# ATSAMC21E17A register map
Vendor: Microchip Technology; Series: SAMC21; File version: 0
CPU: CM0+ r0p0, selectable endian, MPU, no FPU, 2 interrupt priority bits
Registers are 32-bit, read-write, reset 0x0 unless marked. A register's access mark holds for its fields unless they carry their own. Offsets are from the block's base; [hi:lo] are bit positions; lines under a group give offsets from that group; {n}, {i} and the like mark numbered series; 'fields as' and 'values as' point back to an identical list.

## PORT — Port Module
Base 0x41000000; register names take the prefix PORT_
Same registers: PORT_IOBUS 0x60000000 (register names take the prefix PORT_IOBUS_)
{0x0+0x80*i} GROUP[{i}] (i=0..0) group
  0x00 DIR — Data Direction
  0x04 DIRCLR — Data Direction Clear
    [31:0] DIRCLR write-1-clears — Port Data Direction Clear
  0x08 DIRSET — Data Direction Set
    [31:0] DIRSET write-1-sets — Port Data Direction Set
  0x0C DIRTGL — Data Direction Toggle
    [31:0] DIRTGL write-1-toggles — Port Data Direction Toggle
  0x10 OUT — Data Output Value
  0x14 OUTCLR — Data Output Value Clear
    [31:0] OUTCLR write-1-clears — PORT Data Output Value Clear
  0x18 OUTSET — Data Output Value Set
    [31:0] OUTSET write-1-sets — PORT Data Output Value Set
  0x1C OUTTGL — Data Output Value Toggle
    [31:0] OUTTGL write-1-toggles — PORT Data Output Value Toggle
  0x20 IN ro — Data Input Value
  0x24 CTRL — Control
    [31:0] SAMPLING — Input Sampling Mode
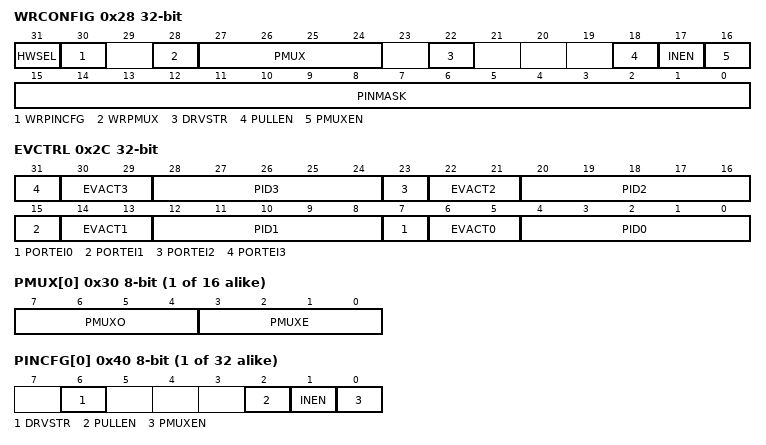
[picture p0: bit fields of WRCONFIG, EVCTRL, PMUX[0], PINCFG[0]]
  0x28 WRCONFIG wo — Write Configuration
    [31] HWSEL — Half-Word Select
    [30] WRPINCFG — Write PINCFG Registers
    [28] WRPMUX — Write PMUX Registers
    [27:24] PMUX — Peripheral Multiplexing Template
    [22] DRVSTR — Output Driver Strength Selection
    [18] PULLEN — Pull Enable
    [17] INEN — Input Enable
    [16] PMUXEN — Select Peripheral Multiplexer
    [15:0] PINMASK — Pin Mask for Multiple Pin Configuration
  0x2C EVCTRL — Event Input Control
    [8n+7] PORTEI{n} (n=0..3) — Port Event Enable Input {n}
    [30:29] EVACT3 — Port Event Action 3
    [8n+4:8n] PID{n} (n=0..3) — Port Event Pin Identifier {n}
    [22:21] EVACT2 — Port Event Action 2
    [14:13] EVACT1 — Port Event Action 1
    [6:5] EVACT0 — Port Event Action 0
      0=OUT (Event output to pin); 1=SET (Set output register of pin on event); 2=CLR (Clear output register of pin on event); 3=TGL (Toggle output register of pin on event)
  {0x30+j} PMUX[{j}] (j=0..15) 8-bit — Peripheral Multiplexing n
    [7:4] PMUXO — Peripheral Multiplexing for Odd-Numbered Pin
    [3:0] PMUXE — Peripheral Multiplexing for Even-Numbered Pin
  {0x40+j} PINCFG[{j}] (j=0..31) 8-bit — Pin Configuration n
    [6] DRVSTR — Output Driver Strength Selection
    [2] PULLEN — Pull Enable
    [1] INEN — Input Enable
    [0] PMUXEN — Select Peripheral Multiplexer

## PTC — Peripheral Touch Controller
Base 0x42005800; register names take the prefix PTC_

## RSTC — Reset Controller
Base 0x40000C00; register names take the prefix RSTC_
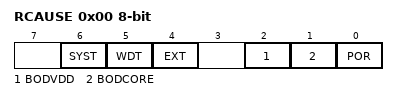
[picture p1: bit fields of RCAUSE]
0x00 RCAUSE 8-bit ro — Reset Cause
  [6] SYST — System Reset Request
  [5] WDT — Watchdog Reset
  [4] EXT — External Reset
  [2] BODVDD — Brown Out VDD Detector Reset
  [1] BODCORE — Brown Out CORE Detector Reset
  [0] POR — Power On Reset

## SUPC — Supply Controller
Base 0x40001800; register names take the prefix SUPC_
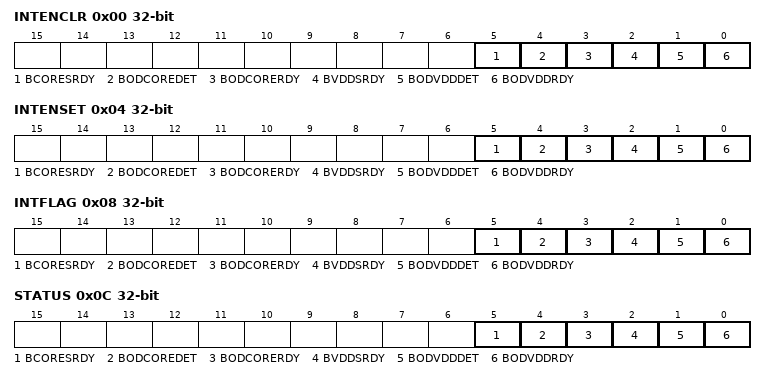
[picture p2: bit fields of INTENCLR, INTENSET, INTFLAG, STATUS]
0x00 INTENCLR — Interrupt Enable Clear
  [5] BCORESRDY — BODCORE Synchronization Ready
  [4] BODCOREDET — BODCORE Detection
  [3] BODCORERDY — BODCORE Ready
  [2] BVDDSRDY — BODVDD Synchronization Ready
  [1] BODVDDDET — BODVDD Detection
  [0] BODVDDRDY — BODVDD Ready
0x04 INTENSET — Interrupt Enable Set
  fields as INTENCLR
0x08 INTFLAG — Interrupt Flag Status and Clear
  [5] BCORESRDY — BODCORE Synchronization Ready
  [4] BODCOREDET — BODCORE Detection
  [3] BODCORERDY — BODCORE Ready
  [2] BVDDSRDY write-1-clears — BODVDD Synchronization Ready
  [1] BODVDDDET write-1-clears — BODVDD Detection
  [0] BODVDDRDY write-1-clears — BODVDD Ready
0x0C STATUS ro — Power and Clocks Status
  fields as INTENCLR
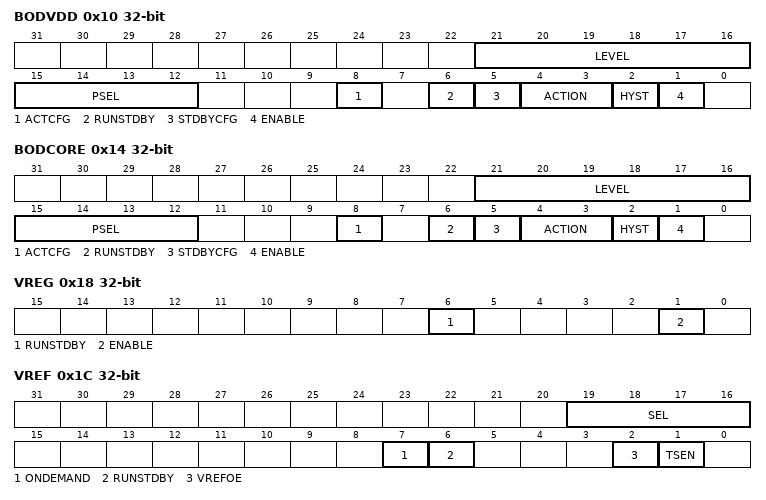
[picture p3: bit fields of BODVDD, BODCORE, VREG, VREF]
0x10 BODVDD — BODVDD Control
  [21:16] LEVEL — Threshold Level for VDD
  [15:12] PSEL — Prescaler Select
    0=DIV2 (Divide clock by 2); 1=DIV4 (Divide clock by 4); 2=DIV8 (Divide clock by 8); 3=DIV16 (Divide clock by 16); 4=DIV32 (Divide clock by 32); 5=DIV64 (Divide clock by 64); 6=DIV128 (Divide clock by 128); 7=DIV256 (Divide clock by 256); 8=DIV512 (Divide clock by 512); 9=DIV1024 (Divide clock by 1024); 10=DIV2048 (Divide clock by 2048); 11=DIV4096 (Divide clock by 4096); 12=DIV8192 (Divide clock by 8192); 13=DIV16384 (Divide clock by 16384); 14=DIV32768 (Divide clock by 32768); 15=DIV65536 (Divide clock by 65536)
  [8] ACTCFG — Configuration in Active mode
  [6] RUNSTDBY — Run during Standby
  [5] STDBYCFG — Configuration in Standby mode
  [4:3] ACTION — Action when Threshold Crossed
    0=NONE (No action); 1=RESET (The BODVDD generates a reset); 2=INT (The BODVDD generates an interrupt)
  [2] HYST — Hysteresis Enable
  [1] ENABLE
0x14 BODCORE — BODCORE Control
  [21:16] LEVEL — Threshold Level
  [15:12] PSEL — Prescaler Select
    values as BODVDD.PSEL
  [8] ACTCFG — Configuration in Active mode
  [6] RUNSTDBY — Run during Standby
  [5] STDBYCFG — Configuration in Standby mode
  [4:3] ACTION — Action when Threshold Crossed
    0=NONE (No action); 1=RESET (The BODCORE generates a reset); 2=INT (The BODCORE generates an interrupt)
  [2] HYST — Hysteresis Enable
  [1] ENABLE
0x18 VREG — VREG Control
  [6] RUNSTDBY — Run during Standby
  [1] ENABLE
0x1C VREF — VREF Control
  [19:16] SEL — Voltage Reference Selection
    0=1V024 (1.024V voltage reference typical value); 2=2V048 (2.048V voltage reference typical value); 3=4V096 (4.096V voltage reference typical value)
  [7] ONDEMAND — On Demand Contrl
  [6] RUNSTDBY — Run during Standby
  [2] VREFOE — Voltage Reference Output Enable
  [1] TSEN — Temperature Sensor Output Enable
